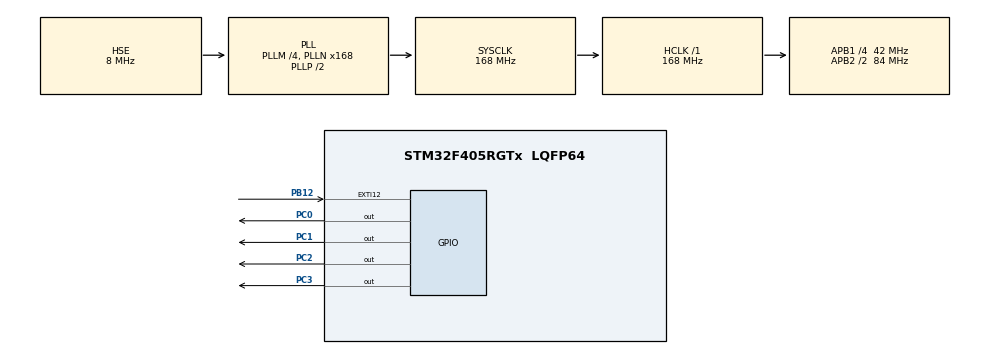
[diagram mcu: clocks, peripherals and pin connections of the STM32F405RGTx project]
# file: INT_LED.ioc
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Mcu.Family=STM32F4
RCC.PLLSourceVirtual=RCC_PLLSOURCE_HSE
PH0-OSC_IN.Signal=RCC_OSC_IN
RCC.CortexFreq_Value=168000000
PC2.Signal=GPIO_Output
PC0.Signal=GPIO_Output
RCC.APB1CLKDivider=RCC_HCLK_DIV4
RCC.SYSCLKSource=RCC_SYSCLKSOURCE_PLLCLK
ProjectManager.StackSize=0x400
PA13.Signal=SYS_JTMS-SWDIO
ProjectManager.TargetToolchain=EWARM V8.32
RCC.HCLKFreq_Value=168000000
RCC.APB2TimFreq_Value=168000000
PC3.Signal=GPIO_Output
RCC.LSE_VALUE=32768
RCC.AHBFreq_Value=168000000
PH0-OSC_IN.Mode=HSE-External-Oscillator
NVIC.EXTI15_10_IRQn=true\:0\:0\:false\:false\:true\:true\:true
RCC.HSE_VALUE=8000000
board=custom
RCC.VCOOutputFreq_Value=336000000
RCC.APB2Freq_Value=84000000
PA14.Mode=Serial_Wire
PH1-OSC_OUT.Signal=RCC_OSC_OUT
PA13.Mode=Serial_Wire
Mcu.Name=STM32F405RGTx
PH1-OSC_OUT.Mode=HSE-External-Oscillator
RCC.48MHZClocksFreq_Value=84000000
RCC.SYSCLKFreq_VALUE=168000000
Mcu.Package=LQFP64
PA14.Signal=SYS_JTCK-SWCLK
ProjectManager.HeapSize=0x200
PB12.GPIO_ModeDefaultEXTI=GPIO_MODE_IT_RISING
RCC.HSI_VALUE=16000000
NVIC.PriorityGroup=NVIC_PRIORITYGROUP_4
RCC.APB2CLKDivider=RCC_HCLK_DIV2
RCC.PLLM=4
RCC.PLLN=168
RCC.APB1TimFreq_Value=84000000
PB12.GPIO_PuPd=GPIO_NOPULL
RCC.APB1Freq_Value=42000000
PC1.Signal=GPIO_Output
PB12.Signal=GPXTI12

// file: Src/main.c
/* USER CODE BEGIN Header */
/**
  ******************************************************************************
  * @file           : main.c
  * @brief          : Main program body
  ******************************************************************************
  * @attention
  *
  * <h2><center>&copy; Copyright (c) 2020 STMicroelectronics.
  * All rights reserved.</center></h2>
  *
  * This software component is licensed by ST under BSD 3-Clause license,
  * the "License"; You may not use this file except in compliance with the
  * License. You may obtain a copy of the License at:
  *                        opensource.org/licenses/BSD-3-Clause
  *
  ******************************************************************************
  */
/* USER CODE END Header */

#include "main.h"
#include "gpio.h"

/* USER CODE BEGIN PV */
unsigned char Time_STOP = 0;
/* USER CODE END PV */

void SystemClock_Config(void);

int main(void)
{

  /* MCU Configuration--------------------------------------------------------*/

  /* Reset of all peripherals, Initializes the Flash interface and the Systick. */
  HAL_Init();

  /* Configure the system clock */
  SystemClock_Config();

  /* Initialize all configured peripherals */
  MX_GPIO_Init();

  /* Infinite loop */
  /* USER CODE BEGIN WHILE */
  unsigned int LED_Data = 0x0001;
  while (1)
  {
    if(!Time_STOP)
    {
      HAL_GPIO_WritePin(GPIOC, GPIO_PIN_All, GPIO_PIN_RESET);
      HAL_GPIO_WritePin(GPIOC, LED_Data, GPIO_PIN_SET);

      HAL_Delay(500);

      LED_Data <<= 1;
      if(LED_Data==0x0010) LED_Data=0x0001;
    }
    /* USER CODE END WHILE */

  }
}

void SystemClock_Config(void)
{
  RCC_OscInitTypeDef RCC_OscInitStruct = {0};
  RCC_ClkInitTypeDef RCC_ClkInitStruct = {0};

  /** Configure the main internal regulator output voltage
  */
  __HAL_RCC_PWR_CLK_ENABLE();
  __HAL_PWR_VOLTAGESCALING_CONFIG(PWR_REGULATOR_VOLTAGE_SCALE1);
  /** Initializes the CPU, AHB and APB busses clocks
  */
  RCC_OscInitStruct.OscillatorType = RCC_OSCILLATORTYPE_HSE;
  RCC_OscInitStruct.HSEState = RCC_HSE_ON;
  RCC_OscInitStruct.PLL.PLLState = RCC_PLL_ON;
  RCC_OscInitStruct.PLL.PLLSource = RCC_PLLSOURCE_HSE;
  RCC_OscInitStruct.PLL.PLLM = 4;
  RCC_OscInitStruct.PLL.PLLN = 168;
  RCC_OscInitStruct.PLL.PLLP = RCC_PLLP_DIV2;
  RCC_OscInitStruct.PLL.PLLQ = 4;
  if (HAL_RCC_OscConfig(&RCC_OscInitStruct) != HAL_OK)
  {
    Error_Handler();
  }
  /** Initializes the CPU, AHB and APB busses clocks
  */
  RCC_ClkInitStruct.ClockType = RCC_CLOCKTYPE_HCLK|RCC_CLOCKTYPE_SYSCLK
                              |RCC_CLOCKTYPE_PCLK1|RCC_CLOCKTYPE_PCLK2;
  RCC_ClkInitStruct.SYSCLKSource = RCC_SYSCLKSOURCE_PLLCLK;
  RCC_ClkInitStruct.AHBCLKDivider = RCC_SYSCLK_DIV1;
  RCC_ClkInitStruct.APB1CLKDivider = RCC_HCLK_DIV4;
  RCC_ClkInitStruct.APB2CLKDivider = RCC_HCLK_DIV2;

  if (HAL_RCC_ClockConfig(&RCC_ClkInitStruct, FLASH_LATENCY_5) != HAL_OK)
  {
    Error_Handler();
  }
}

/* USER CODE BEGIN 4 */
void HAL_GPIO_EXTI_Callback(uint16_t GPIO_Pin)
{
  //HAL_GPIO_TogglePin(GPIOC, GPIO_PIN_0);
  if(GPIO_Pin == GPIO_PIN_12)
  {
    if(Time_STOP) Time_STOP=0;
    else Time_STOP=1;
  }
}
/* USER CODE END 4 */

void Error_Handler(void)
{
}

/************************ (C) COPYRIGHT STMicroelectronics *****END OF FILE****/
